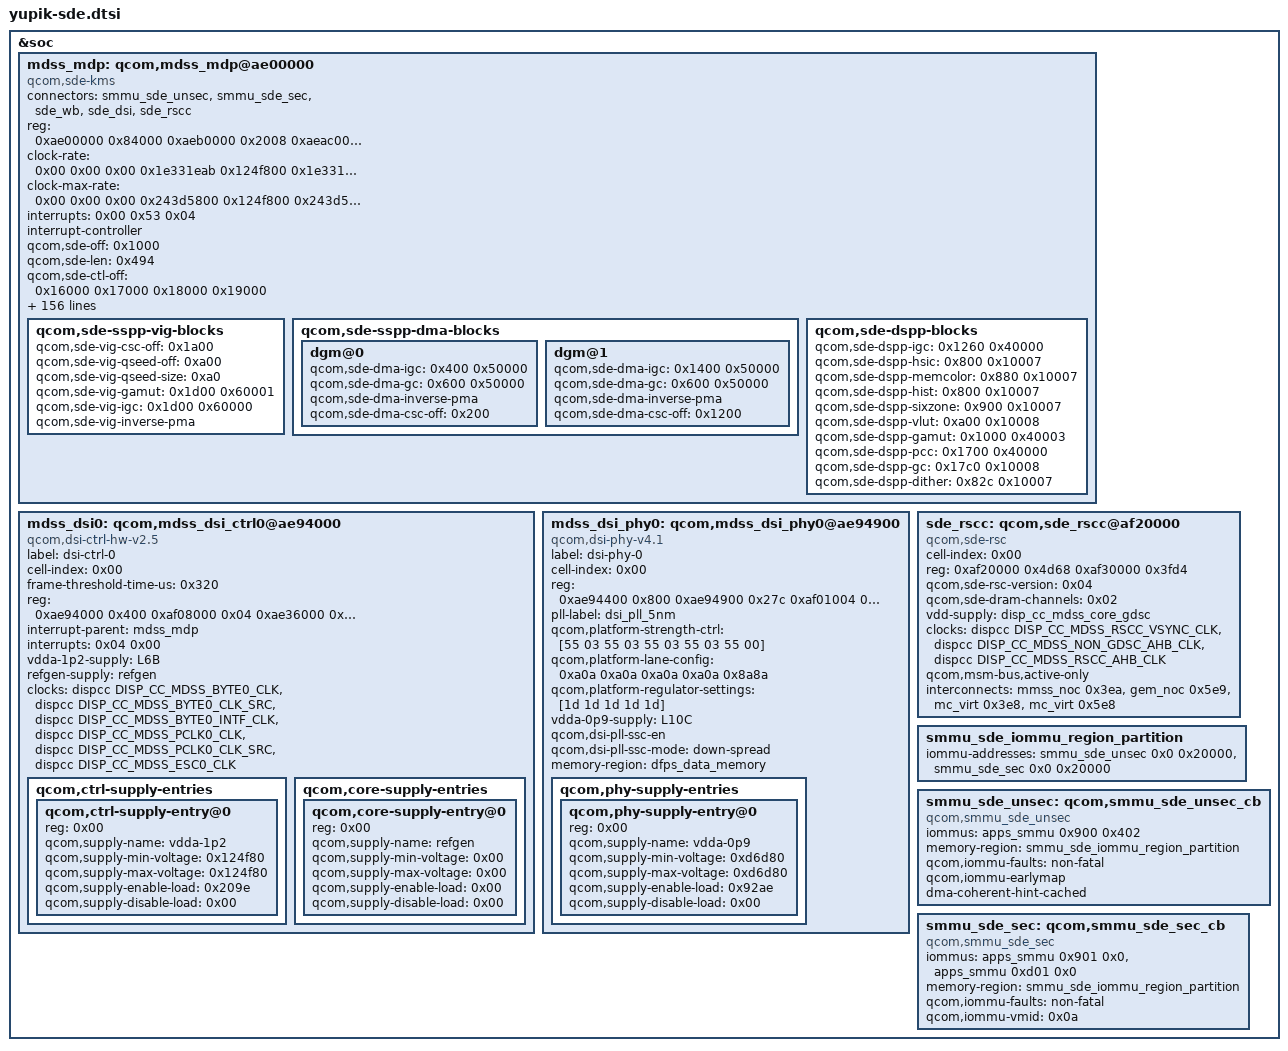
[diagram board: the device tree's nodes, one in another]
// SPDX-License-Identifier: GPL-2.0-only
/*
 * SoC display nodes (SDE 7.2 MDP, DSI0 controller + PHY, RSC, SMMU contexts). The 6.12 yupik
 * base has none of them. DisplayPort (sde_dp, ext_disp) is not carried over.
 * GENERATED by tools/gen-dts.py from downstream-dt/a52sxq-r02.dts (the merged tree the
 * phone boots: yupik.dtb + overlay a52sxq_kor_single_w00_r02, used by hardware revisions
 * 2 and later, so 3 and 4 too). Values are byte-for-byte the phone's; only phandles were
 * turned into labels. Do not edit by hand; edit the generator.
 */

&soc {
	mdss_mdp: qcom,mdss_mdp@ae00000 {
		connectors = <&smmu_sde_unsec &smmu_sde_sec &sde_wb &sde_dsi &sde_rscc>;
		#cooling-cells = <0x02>;
		compatible = "qcom,sde-kms";
		reg = <0xae00000 0x84000 0xaeb0000 0x2008 0xaeac000 0x800>;
		reg-names = "mdp_phys", "vbif_phys", "regdma_phys";
		clock-rate = <0x00 0x00 0x00 0x1e331eab 0x124f800 0x1e331eab 0x124f800>;
		clock-max-rate = <0x00 0x00 0x00 0x243d5800 0x124f800 0x243d5800 0x243d5800>;
		interrupts = <0x00 0x53 0x04>;
		interrupt-controller;
		#interrupt-cells = <0x01>;
		qcom,sde-off = <0x1000>;
		qcom,sde-len = <0x494>;
		qcom,sde-ctl-off = <0x16000 0x17000 0x18000 0x19000>;
		qcom,sde-ctl-size = <0x1e8>;
		qcom,sde-ctl-display-pref = "primary", "none", "none", "none";
		qcom,sde-mixer-off = <0x45000 0x45000 0x47000 0x48000>;
		qcom,sde-mixer-size = <0x320>;
		qcom,sde-mixer-display-pref = "primary", "none", "none", "none";
		qcom,sde-mixer-cwb-pref = "none", "cwb", "none", "none";
		qcom,sde-dspp-top-off = <0x1300>;
		qcom,sde-dspp-top-size = <0x80>;
		qcom,sde-dspp-off = <0x55000>;
		qcom,sde-dspp-size = <0x1800>;
		qcom,sde-dspp-rc-version = <0x10000>;
		qcom,sde-dspp-rc-off = <0x15800>;
		qcom,sde-dspp-rc-size = <0x100>;
		qcom,sde-dspp-rc-mem-size = <0xaa0>;
		qcom,sde-wb-off = <0x66000>;
		qcom,sde-wb-size = <0x2c8>;
		qcom,sde-wb-xin-id = <0x06>;
		qcom,sde-wb-id = <0x02>;
		qcom,sde-wb-clk-ctrl = <0x2bc 0x10>;
		qcom,sde-wb-clk-status = <0x3bc 0x14>;
		qcom,sde-intf-off = <0x35000 0x36000 0x3a000>;
		qcom,sde-intf-size = <0x2c4>;
		qcom,sde-intf-type = "dp", "dsi", "dp";
		qcom,sde-intf-tear-irq-off = <0x00 0x36800 0x00>;
		qcom,sde-pp-off = <0x6a000 0x6b000 0x6c000 0x6d000>;
		qcom,sde-pp-slave = <0x00 0x00 0x00 0x00>;
		qcom,sde-pp-size = <0xd4>;
		qcom,sde-pp-merge-3d-id = <0x00 0x00 0x01 0x01>;
		qcom,sde-merge-3d-off = <0x50000 0x50000>;
		qcom,sde-merge-3d-size = <0x10>;
		qcom,sde-cdm-off = <0x7a200>;
		qcom,sde-cdm-size = <0x224>;
		qcom,sde-dsc-off = <0x81000>;
		qcom,sde-dsc-size = <0x10>;
		qcom,sde-dsc-hw-rev = "dsc_1_2";
		qcom,sde-dsc-enc = <0x100>;
		qcom,sde-dsc-enc-size = <0x100>;
		qcom,sde-dsc-ctl = <0xf00>;
		qcom,sde-dsc-ctl-size = <0x10>;
		qcom,sde-dsc-native422-supp = <0x01>;
		qcom,sde-dsc-linewidth = <0x800>;
		qcom,sde-dither-off = <0xe0 0xe0 0xe0 0xe0>;
		qcom,sde-dither-version = <0x20000>;
		qcom,sde-dither-size = <0x20>;
		qcom,sde-sspp-type = "vig", "dma", "dma", "dma";
		qcom,sde-sspp-off = <0x5000 0x25000 0x27000 0x29000>;
		qcom,sde-sspp-src-size = <0x1f8>;
		qcom,sde-sspp-xin-id = <0x00 0x01 0x05 0x09>;
		qcom,sde-sspp-excl-rect = <0x01 0x01 0x01 0x01>;
		qcom,sde-sspp-smart-dma-priority = <0x04 0x01 0x02 0x03>;
		qcom,sde-smart-dma-rev = "smart_dma_v2p5";
		qcom,sde-mixer-pair-mask = <0x00 0x00 0x04 0x03>;
		qcom,sde-mixer-blend-op-off = <0x20 0x38 0x50 0x68 0x80 0x98 0xb0 0xc8 0xe0 0xf8 0x110>;
		qcom,sde-max-per-pipe-bw-kbps = <0x419ce0 0x419ce0 0x419ce0 0x419ce0>;
		qcom,sde-max-per-pipe-bw-high-kbps = <0x419ce0 0x419ce0 0x419ce0 0x419ce0>;
		qcom,sde-sspp-clk-ctrl = <0x2ac 0x00 0x2ac 0x08 0x2b4 0x08 0x2c4 0x08>;
		qcom,sde-sspp-clk-status = <0x2b0 0x00 0x2b0 0x0c 0x2b8 0x0c 0x2c8 0x0c>;
		qcom,sde-sspp-csc-off = <0x1a00>;
		qcom,sde-csc-type = "csc-10bit";
		qcom,sde-qseed-sw-lib-rev = "qseedv3lite";
		qcom,sde-qseed-scalar-version = <0x3000>;
		qcom,sde-sspp-qseed-off = <0xa00>;
		qcom,sde-mixer-linewidth = <0xa00>;
		qcom,sde-sspp-linewidth = <0x960>;
		qcom,sde-vig-sspp-linewidth = <0x1000>;
		qcom,sde-scaling-linewidth = <0xa00>;
		qcom,sde-wb-linewidth = <0x1000>;
		qcom,sde-wb-linewidth-linear = <0x1000>;
		qcom,sde-mixer-blendstages = <0x09>;
		qcom,sde-highest-bank-bit = <0x08 0x02 0x07 0x01>;
		/*
		 * 6.12 (r7) encoding SDE_HW_VER(3,0,0). The 5.4 tree's <0x300> is read raw into
		 * ubwc_rev by r7, so no IS_UBWC_xx check matched, the SSPP UBWC static register was
		 * never written and every UBWC buffer showed green and blocky (owner, 2026-11-13).
		 */
		qcom,sde-ubwc-version = <0x30000000>;
		qcom,sde-ubwc-swizzle = <0x06>;
		qcom,sde-ubwc-bw-calc-version = <0x01>;
		qcom,sde-ubwc-static = <0x01>;
		qcom,sde-macrotile-mode = <0x01>;
		qcom,sde-smart-panel-align-mode = <0x0c>;
		qcom,sde-panic-per-pipe;
		qcom,sde-has-cdp;
		qcom,sde-has-src-split;
		qcom,sde-pipe-order-version = <0x01>;
		qcom,sde-has-dim-layer;
		qcom,sde-max-trusted-vm-displays = <0x01>;
		qcom,sde-max-bw-low-kbps = <0x47b760>;
		qcom,sde-max-bw-high-kbps = <0x864700>;
		qcom,sde-min-core-ib-kbps = <0x2625a0>;
		qcom,sde-min-llcc-ib-kbps = <0x00>;
		qcom,sde-min-dram-ib-kbps = <0x186a00>;
		qcom,sde-dram-channels = <0x02>;
		qcom,sde-num-nrt-paths = <0x00>;
		qcom,sde-uidle-off = <0x80000>;
		qcom,sde-uidle-size = <0x70>;
		qcom,sde-vbif-off = <0x00>;
		qcom,sde-vbif-size = <0x1040>;
		qcom,sde-vbif-id = <0x00>;
		qcom,sde-vbif-memtype-0 = <0x03 0x03 0x03 0x03 0x03 0x03 0x03 0x03>;
		qcom,sde-vbif-memtype-1 = <0x03 0x03 0x03 0x03 0x03 0x03>;
		qcom,sde-vbif-qos-rt-remap = <0x03 0x03 0x04 0x04 0x05 0x05 0x06 0x06>;
		qcom,sde-vbif-qos-nrt-remap = <0x03 0x03 0x03 0x03 0x03 0x03 0x03 0x03>;
		qcom,sde-vbif-qos-cwb-remap = <0x03 0x03 0x04 0x04 0x05 0x05 0x06 0x03>;
		qcom,sde-vbif-qos-lutdma-remap = <0x03 0x03 0x03 0x03 0x04 0x04 0x04 0x04>;
		qcom,sde-danger-lut = <0xffff 0xffff 0x00 0x00 0xffff 0xffff>;
		qcom,sde-safe-lut = <0xff00 0xff00 0xffff 0x01 0xff00 0xff00>;
		qcom,sde-qos-lut-linear = <0x112233 0x44556677>;
		qcom,sde-qos-lut-macrotile = <0x112233 0x44556677>;
		qcom,sde-qos-lut-macrotile-qseed = <0x112233 0x66777777>;
		qcom,sde-qos-lut-linear-qseed = <0x112233 0x66777777>;
		qcom,sde-qos-lut-nrt = <0x00 0x00>;
		qcom,sde-qos-lut-cwb = <0x66666666 0x66666540>;
		qcom,sde-cdp-setting = <0x01 0x01 0x01 0x00>;
		qcom,sde-qos-cpu-mask = <0x03>;
		qcom,sde-qos-cpu-mask-performance = <0x0f>;
		qcom,sde-qos-cpu-dma-latency = <0x12c>;
		qcom,sde-qos-cpu-irq-latency = <0x12c>;
		qcom,sde-reg-dma-off = <0x00 0x400>;
		qcom,sde-reg-dma-id = <0x00 0x01>;
		qcom,sde-reg-dma-version = <0x20000>;
		qcom,sde-reg-dma-trigger-off = <0x119c>;
		qcom,sde-reg-dma-xin-id = <0x07>;
		qcom,sde-reg-dma-clk-ctrl = <0x2bc 0x14>;
		qcom,sde-secure-sid-mask = <0x901 0xd01>;
		qcom,sde-reg-bus,vectors-KBps = <0x00 0x00 0x00 0x12110 0x00 0x24220 0x00 0x40b28>;
		clocks = <&gcc GCC_DISP_HF_AXI_CLK>, <&gcc GCC_DISP_SF_AXI_CLK>, <&dispcc DISP_CC_MDSS_AHB_CLK>, <&dispcc DISP_CC_MDSS_MDP_CLK>, <&dispcc DISP_CC_MDSS_VSYNC_CLK>, <&dispcc DISP_CC_MDSS_MDP_LUT_CLK>, <&dispcc DISP_CC_MDSS_ROT_CLK>;
		clock-names = "gcc_bus", "gcc_nrt_bus", "iface_clk", "core_clk", "vsync_clk", "lut_clk", "rot_clk";
		interconnects = <&mmss_noc 0x27>, <&mc_virt 0x200>, <&gem_noc 0x2>, <&cnoc2 0x20d>;
		interconnect-names = "qcom,sde-data-bus0", "qcom,sde-reg-bus";
		qcom,sde-has-idle-pc;
		qcom,sde-dspp-ltm-version = <0x10001>;
		qcom,sde-dspp-ltm-off = <0x15300>;















		qcom,sde-sspp-vig-blocks {
			qcom,sde-vig-csc-off = <0x1a00>;
			qcom,sde-vig-qseed-off = <0xa00>;
			qcom,sde-vig-qseed-size = <0xa0>;
			qcom,sde-vig-gamut = <0x1d00 0x60001>;
			qcom,sde-vig-igc = <0x1d00 0x60000>;
			qcom,sde-vig-inverse-pma;
		};

		qcom,sde-sspp-dma-blocks {

			dgm@0 {
				qcom,sde-dma-igc = <0x400 0x50000>;
				qcom,sde-dma-gc = <0x600 0x50000>;
				qcom,sde-dma-inverse-pma;
				qcom,sde-dma-csc-off = <0x200>;
			};

			dgm@1 {
				qcom,sde-dma-igc = <0x1400 0x50000>;
				qcom,sde-dma-gc = <0x600 0x50000>;
				qcom,sde-dma-inverse-pma;
				qcom,sde-dma-csc-off = <0x1200>;
			};
		};

		qcom,sde-dspp-blocks {
			qcom,sde-dspp-igc = <0x1260 0x40000>;
			qcom,sde-dspp-hsic = <0x800 0x10007>;
			qcom,sde-dspp-memcolor = <0x880 0x10007>;
			qcom,sde-dspp-hist = <0x800 0x10007>;
			qcom,sde-dspp-sixzone = <0x900 0x10007>;
			qcom,sde-dspp-vlut = <0xa00 0x10008>;
			qcom,sde-dspp-gamut = <0x1000 0x40003>;
			qcom,sde-dspp-pcc = <0x1700 0x40000>;
			qcom,sde-dspp-gc = <0x17c0 0x10008>;
			qcom,sde-dspp-dither = <0x82c 0x10007>;
		};
	};

	mdss_dsi0: qcom,mdss_dsi_ctrl0@ae94000 {
		compatible = "qcom,dsi-ctrl-hw-v2.5";
		label = "dsi-ctrl-0";
		cell-index = <0x00>;
		frame-threshold-time-us = <0x320>;
		reg = <0xae94000 0x400 0xaf08000 0x04 0xae36000 0x300>;
		reg-names = "dsi_ctrl", "disp_cc_base", "mdp_intf_base";
		interrupt-parent = <&mdss_mdp>;
		interrupts = <0x04 0x00>;
		vdda-1p2-supply = <&L6B>;
		refgen-supply = <&refgen>;
		clocks = <&dispcc DISP_CC_MDSS_BYTE0_CLK>, <&dispcc DISP_CC_MDSS_BYTE0_CLK_SRC>, <&dispcc DISP_CC_MDSS_BYTE0_INTF_CLK>, <&dispcc DISP_CC_MDSS_PCLK0_CLK>, <&dispcc DISP_CC_MDSS_PCLK0_CLK_SRC>, <&dispcc DISP_CC_MDSS_ESC0_CLK>;
		clock-names = "byte_clk", "byte_clk_rcg", "byte_intf_clk", "pixel_clk", "pixel_clk_rcg", "esc_clk";

		qcom,ctrl-supply-entries {
			#address-cells = <0x01>;
			#size-cells = <0x00>;

			qcom,ctrl-supply-entry@0 {
				reg = <0x00>;
				qcom,supply-name = "vdda-1p2";
				qcom,supply-min-voltage = <0x124f80>;
				qcom,supply-max-voltage = <0x124f80>;
				qcom,supply-enable-load = <0x209e>;
				qcom,supply-disable-load = <0x00>;
			};
		};

		qcom,core-supply-entries {
			#address-cells = <0x01>;
			#size-cells = <0x00>;

			qcom,core-supply-entry@0 {
				reg = <0x00>;
				qcom,supply-name = "refgen";
				qcom,supply-min-voltage = <0x00>;
				qcom,supply-max-voltage = <0x00>;
				qcom,supply-enable-load = <0x00>;
				qcom,supply-disable-load = <0x00>;
			};
		};
	};

	mdss_dsi_phy0: qcom,mdss_dsi_phy0@ae94900 {
		compatible = "qcom,dsi-phy-v4.1";
		label = "dsi-phy-0";
		cell-index = <0x00>;
		#clock-cells = <0x01>;
		reg = <0xae94400 0x800 0xae94900 0x27c 0xaf01004 0x08 0xae94200 0x100>;
		reg-names = "dsi_phy", "pll_base", "gdsc_base", "dyn_refresh_base";
		pll-label = "dsi_pll_5nm";
		qcom,platform-strength-ctrl = [55 03 55 03 55 03 55 03 55 00];
		qcom,platform-lane-config = <0xa0a 0xa0a 0xa0a 0xa0a 0x8a8a>;
		qcom,platform-regulator-settings = [1d 1d 1d 1d 1d];
		vdda-0p9-supply = <&L10C>;
		qcom,dsi-pll-ssc-en;
		qcom,dsi-pll-ssc-mode = "down-spread";
		memory-region = <&dfps_data_memory>;

		qcom,phy-supply-entries {
			#address-cells = <0x01>;
			#size-cells = <0x00>;

			qcom,phy-supply-entry@0 {
				reg = <0x00>;
				qcom,supply-name = "vdda-0p9";
				qcom,supply-min-voltage = <0xd6d80>;
				qcom,supply-max-voltage = <0xd6d80>;
				qcom,supply-enable-load = <0x92ae>;
				qcom,supply-disable-load = <0x00>;
			};
		};
	};

	sde_rscc: qcom,sde_rscc@af20000 {
		cell-index = <0x00>;
		compatible = "qcom,sde-rsc";
		reg = <0xaf20000 0x4d68 0xaf30000 0x3fd4>;
		reg-names = "drv", "wrapper";
		qcom,sde-rsc-version = <0x04>;
		qcom,sde-dram-channels = <0x02>;
		vdd-supply = <&disp_cc_mdss_core_gdsc>;
		clocks = <&dispcc DISP_CC_MDSS_RSCC_VSYNC_CLK>, <&dispcc DISP_CC_MDSS_NON_GDSC_AHB_CLK>, <&dispcc DISP_CC_MDSS_RSCC_AHB_CLK>;
		clock-names = "vsync_clk", "gdsc_clk", "iface_clk";
		qcom,msm-bus,active-only;
		interconnects = <&mmss_noc 0x3ea>, <&gem_noc 0x5e9>, <&mc_virt 0x3e8>, <&mc_virt 0x5e8>;
		interconnect-names = "qcom,sde-data-bus0", "qcom,sde-ebi-bus";
	};

	/*
	 * 5.4: qcom,iommu-dma-addr-pool = <0x20000 0xfffe0000> on both context banks (DMA API
	 * IOVAs in 0x20000..0xffffffff). 6.12/6.18 arm-smmu only WARNs on that property, so the
	 * window is written the way Qualcomm's 6.12 *-sde.dtsi do (smmu_sde_iommu_region_partition):
	 * reserve [0, 0x20000). The window ends at 4 GiB, which the 32-bit default DMA mask of
	 * these devices already enforces. msm_smmu.c never read the pool (it takes the DMA API
	 * domain and maps the splash 1:1 with iommu_map). Entries in /soc's 1+1 cell format.
	 */
	smmu_sde_iommu_region_partition: smmu_sde_iommu_region_partition {
		iommu-addresses = <&smmu_sde_unsec 0x0 0x20000>,
				  <&smmu_sde_sec 0x0 0x20000>;
	};

	smmu_sde_unsec: qcom,smmu_sde_unsec_cb {
		compatible = "qcom,smmu_sde_unsec";
		iommus = <&apps_smmu 0x900 0x402>;
		memory-region = <&smmu_sde_iommu_region_partition>;
		qcom,iommu-faults = "non-fatal";
		qcom,iommu-earlymap;
		dma-coherent-hint-cached;
	};

	smmu_sde_sec: qcom,smmu_sde_sec_cb {
		compatible = "qcom,smmu_sde_sec";
		iommus = <&apps_smmu 0x901 0x0>, <&apps_smmu 0xd01 0x0>;
		memory-region = <&smmu_sde_iommu_region_partition>;
		qcom,iommu-faults = "non-fatal";
		qcom,iommu-vmid = <0x0a>;
	};
};
